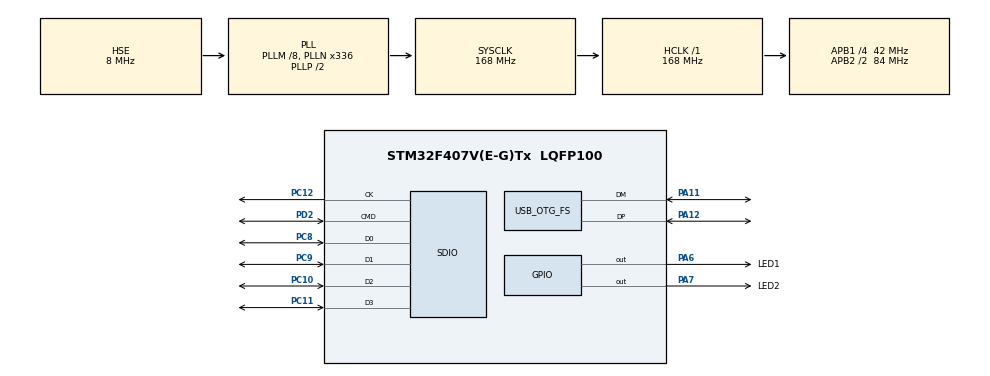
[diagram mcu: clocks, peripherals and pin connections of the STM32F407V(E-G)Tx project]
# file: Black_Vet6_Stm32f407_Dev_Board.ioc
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Mcu.Family=STM32F4
Mcu.Name=STM32F407V(E-G)Tx
Mcu.Package=LQFP100
NVIC.OTG_FS_IRQn=true\:0\:0\:false\:false\:true\:false\:true\:true
NVIC.PriorityGroup=NVIC_PRIORITYGROUP_4
PA11.Mode=Device_Only
PA11.Signal=USB_OTG_FS_DM
PA12.Mode=Device_Only
PA12.Signal=USB_OTG_FS_DP
PA6.GPIO_Label=LED1
PA6.GPIO_Speed=GPIO_SPEED_FREQ_HIGH
PA6.Signal=GPIO_Output
PA7.GPIO_Label=LED2
PA7.GPIO_Speed=GPIO_SPEED_FREQ_HIGH
PA7.Signal=GPIO_Output
PC10.Mode=SD_4_bits_Wide_bus
PC10.Signal=SDIO_D2
PC11.Mode=SD_4_bits_Wide_bus
PC11.Signal=SDIO_D3
PC12.Mode=SD_4_bits_Wide_bus
PC12.Signal=SDIO_CK
PC8.Mode=SD_4_bits_Wide_bus
PC8.Signal=SDIO_D0
PC9.Mode=SD_4_bits_Wide_bus
PC9.Signal=SDIO_D1
PD2.Mode=SD_4_bits_Wide_bus
PD2.Signal=SDIO_CMD
PH0-OSC_IN.Mode=HSE-External-Oscillator
PH0-OSC_IN.Signal=RCC_OSC_IN
PH1-OSC_OUT.Mode=HSE-External-Oscillator
PH1-OSC_OUT.Signal=RCC_OSC_OUT
ProjectManager.HeapSize=0x200
ProjectManager.StackSize=0x400
ProjectManager.TargetToolchain=CMake
RCC.48MHZClocksFreq_Value=48000000
RCC.AHBFreq_Value=168000000
RCC.APB1CLKDivider=RCC_HCLK_DIV4
RCC.APB1Freq_Value=42000000
RCC.APB1TimFreq_Value=84000000
RCC.APB2CLKDivider=RCC_HCLK_DIV2
RCC.APB2Freq_Value=84000000
RCC.APB2TimFreq_Value=168000000
RCC.CortexFreq_Value=168000000
RCC.HCLKFreq_Value=168000000
RCC.HSE_VALUE=8000000
RCC.HSI_VALUE=16000000
RCC.LSE_VALUE=32768
RCC.PLLM=8
RCC.PLLN=336
RCC.PLLQ=7
RCC.PLLSourceVirtual=RCC_PLLSOURCE_HSE
RCC.SYSCLKFreq_VALUE=168000000
RCC.SYSCLKSource=RCC_SYSCLKSOURCE_PLLCLK
RCC.VCOOutputFreq_Value=336000000
USB_DEVICE.CLASS_NAME_FS=CDC
USB_DEVICE.VirtualMode-CDC_FS=Cdc
USB_DEVICE.VirtualModeFS=Cdc_FS
USB_OTG_FS.VirtualMode=Device_Only
VP_USB_DEVICE_VS_USB_DEVICE_CDC_FS.Mode=CDC_FS
board=custom

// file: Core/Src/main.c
/* USER CODE BEGIN Header */
/**
  ******************************************************************************
  * @file           : main.c
  * @brief          : Main program body
  ******************************************************************************
  * @attention
  *
  * Copyright (c) 2025 STMicroelectronics.
  * All rights reserved.
  *
  * This software is licensed under terms that can be found in the LICENSE file
  * in the root directory of this software component.
  * If no LICENSE file comes with this software, it is provided AS-IS.
  *
  ******************************************************************************
  */
/* USER CODE END Header */
#include "main.h"
#include "stm32f4xx_hal_gpio.h"
#include "usb_device.h"
#include "usbd_cdc_if.h"
#include "configuration.h"
#include "safeguards.h"

SD_HandleTypeDef hsd;

void SystemClock_Config(void);
static void MX_GPIO_Init(void);

#ifdef ENABLE_SD
static void MX_SDIO_SD_Init(void);
#endif

// Call this anywhere in your code to send a string over USB CDC
// send string over CDC, retrying briefly if the stack is busy
void CDCSerialPrint(const char *str)
{
    if (str == NULL) return;

    uint16_t len = (uint16_t)strlen(str);
    uint32_t start = HAL_GetTick();

    // try for up to 2 seconds to send (adjust timeout if you want)
    while ((HAL_GetTick() - start) < 2000U)
    {
        uint8_t res = CDC_Transmit_FS((uint8_t*)str, len);
        if (res == USBD_OK)        // sent
            return;
        if (res == USBD_FAIL)      // unrecoverable
            return;
        // USBD_BUSY or other: wait a bit and retry
        HAL_Delay(10);
    }
}

#ifndef ENABLE_SD
// initialize USB device and send a single "connected" line once the host is ready
void CDC_SERIAL_INIT(void)
{
    MX_USB_DEVICE_Init();

    // Try to send a "Connected" message once the device is ready.
    // We don't block forever — try for up to 5 seconds.
    const char *msg = "Connected to STM32F407VET6 via USB CDC | SD CARD DISABLED WHILE CDC IS ENABLED Uncomment ENABLE_SD in configuration.h to enable SD card functionality Note disables CDC!\r\n";
    uint32_t start = HAL_GetTick();

    while ((HAL_GetTick() - start) < 5000U)
    {
        uint8_t res = CDC_Transmit_FS((uint8_t*)msg, (uint16_t)strlen(msg));
        if (res == USBD_OK) break; // sent; done
        // if busy, wait and retry
        HAL_Delay(50);
    }
}
#endif
int main(void)
{

  /* MCU Configuration--------------------------------------------------------*/

  /* Reset of all peripherals, Initializes the Flash interface and the Systick. */
  HAL_Init();

  /* Configure the system clock */
  SystemClock_Config();

  /* Initialize all configured peripherals */
  MX_GPIO_Init();

  //Disable SD initialization if USB CDC is desired, usbcdc not able to work with SD enabled currently
  #ifdef ENABLE_SD
    MX_SDIO_SD_Init();
    // SD card functionality enabled - do not initialize USB CDC
  #else
    CDC_SERIAL_INIT();
  #endif

  /* Make sure SysTick is highest priority */
  HAL_NVIC_SetPriority(SysTick_IRQn, 0, 0);
  /* Lower USB OTG FS IRQ priority to prevent it from starving main loop */
  HAL_NVIC_SetPriority(OTG_FS_IRQn, 6, 0);

   /* --- FIXES ADDED HERE --- */
  /* Ensure SystemCoreClock is updated and SysTick is configured properly in case USB init changed clocks */
  SystemCoreClockUpdate();
  HAL_InitTick(TICK_INT_PRIORITY);  // Re-initialize SysTick for HAL_Delay

  /* Re-initialize LED GPIOs in case USB init changed them */
  GPIO_InitTypeDef GPIO_InitStruct = {0};
  __HAL_RCC_GPIOA_CLK_ENABLE();
  GPIO_InitStruct.Pin = LED1_Pin|LED2_Pin;
  GPIO_InitStruct.Mode = GPIO_MODE_OUTPUT_PP;
  GPIO_InitStruct.Pull = GPIO_NOPULL;
  GPIO_InitStruct.Speed = GPIO_SPEED_FREQ_LOW;
  HAL_GPIO_Init(GPIOA, &GPIO_InitStruct);
  HAL_GPIO_WritePin(GPIOA, LED1_Pin|LED2_Pin, GPIO_PIN_SET);
  HAL_GPIO_WritePin(GPIOA, LED1_Pin, GPIO_PIN_SET);

  /* Infinite loop */
  /* USER CODE BEGIN WHILE */
 while(1)
{
    /* Toggle LED2 */
    HAL_GPIO_TogglePin(GPIOA, LED2_Pin);

    #if defined(ENABLE_USB_CDC_LED_INDICATOR)
      HAL_GPIO_WritePin(GPIOA, LED1_Pin, GPIO_PIN_SET);
    #endif
    /* Wait 500 ms */
    HAL_Delay(500);
}

  /* USER CODE END WHILE */

}

void SystemClock_Config(void)
{
  RCC_OscInitTypeDef RCC_OscInitStruct = {0};
  RCC_ClkInitTypeDef RCC_ClkInitStruct = {0};

  /** Configure the main internal regulator output voltage
  */
  __HAL_RCC_PWR_CLK_ENABLE();
  __HAL_PWR_VOLTAGESCALING_CONFIG(PWR_REGULATOR_VOLTAGE_SCALE1);

  /** Initializes the RCC Oscillators according to the specified parameters
  * in the RCC_OscInitTypeDef structure.
  */
  RCC_OscInitStruct.OscillatorType = RCC_OSCILLATORTYPE_HSE;
  RCC_OscInitStruct.HSEState = RCC_HSE_ON;
  RCC_OscInitStruct.PLL.PLLState = RCC_PLL_ON;
  RCC_OscInitStruct.PLL.PLLSource = RCC_PLLSOURCE_HSE;
  RCC_OscInitStruct.PLL.PLLM = 8;
  RCC_OscInitStruct.PLL.PLLN = 336;
  RCC_OscInitStruct.PLL.PLLP = RCC_PLLP_DIV2;
  RCC_OscInitStruct.PLL.PLLQ = 7;
  if (HAL_RCC_OscConfig(&RCC_OscInitStruct) != HAL_OK)
  {
    Error_Handler();
  }

  /** Initializes the CPU, AHB and APB buses clocks
  */
  RCC_ClkInitStruct.ClockType = RCC_CLOCKTYPE_HCLK|RCC_CLOCKTYPE_SYSCLK
                              |RCC_CLOCKTYPE_PCLK1|RCC_CLOCKTYPE_PCLK2;
  RCC_ClkInitStruct.SYSCLKSource = RCC_SYSCLKSOURCE_PLLCLK;
  RCC_ClkInitStruct.AHBCLKDivider = RCC_SYSCLK_DIV1;
  RCC_ClkInitStruct.APB1CLKDivider = RCC_HCLK_DIV4;
  RCC_ClkInitStruct.APB2CLKDivider = RCC_HCLK_DIV2;

  if (HAL_RCC_ClockConfig(&RCC_ClkInitStruct, FLASH_LATENCY_5) != HAL_OK)
  {
    Error_Handler();
  }
}

#ifdef ENABLE_SD
static void MX_SDIO_SD_Init(void)
{
  hsd.Instance = SDIO;
  hsd.Init.ClockEdge = SDIO_CLOCK_EDGE_RISING;
  hsd.Init.ClockBypass = SDIO_CLOCK_BYPASS_DISABLE;
  hsd.Init.ClockPowerSave = SDIO_CLOCK_POWER_SAVE_DISABLE;
  hsd.Init.BusWide = SDIO_BUS_WIDE_1B;
  hsd.Init.HardwareFlowControl = SDIO_HARDWARE_FLOW_CONTROL_DISABLE;
  hsd.Init.ClockDiv = 0;
  if (HAL_SD_Init(&hsd) != HAL_OK)
  {
    Error_Handler();
  }
  if (HAL_SD_ConfigWideBusOperation(&hsd, SDIO_BUS_WIDE_4B) != HAL_OK)
  {
    Error_Handler();
  }
}
#endif
static void MX_GPIO_Init(void)
{
  GPIO_InitTypeDef GPIO_InitStruct = {0};

  /* GPIO Ports Clock Enable */
  __HAL_RCC_GPIOH_CLK_ENABLE();
  __HAL_RCC_GPIOA_CLK_ENABLE();
  __HAL_RCC_GPIOC_CLK_ENABLE();
  __HAL_RCC_GPIOD_CLK_ENABLE();

  /*Configure GPIO pin Output Level */
  HAL_GPIO_WritePin(GPIOA, LED1_Pin|LED2_Pin, GPIO_PIN_SET);

  /*Configure GPIO pins : LED1_Pin LED2_Pin */
  GPIO_InitStruct.Pin = LED1_Pin|LED2_Pin;
  GPIO_InitStruct.Mode = GPIO_MODE_OUTPUT_PP;
  GPIO_InitStruct.Pull = GPIO_NOPULL;
  GPIO_InitStruct.Speed = GPIO_SPEED_FREQ_HIGH;
  HAL_GPIO_Init(GPIOA, &GPIO_InitStruct);
}

void Error_Handler(void)
{
  __disable_irq();
  while (1)
  {
  }
}
